# PY32F030xx register map
Vendor: Puya; Series: PY32F0; File version: 1.0.0
CPU: CM0+ r0p1, little endian, no MPU, no FPU, 4 interrupt priority bits
Registers are 32-bit, read-write, reset 0x0 unless marked. A register's access mark holds for its fields unless they carry their own. Offsets are from the block's base; [hi:lo] are bit positions; {n}, {i} and the like mark numbered series; 'fields as' and 'values as' point back to an identical list.

## COMP1 — Comparator
Base 0x40010200
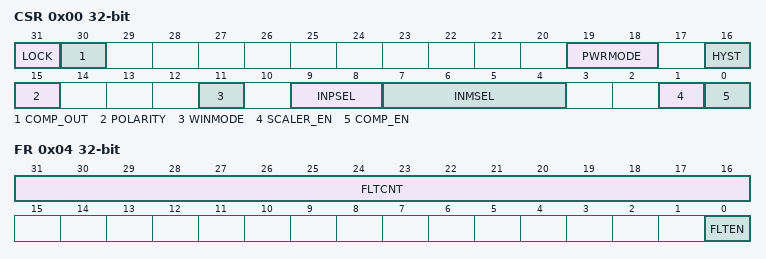
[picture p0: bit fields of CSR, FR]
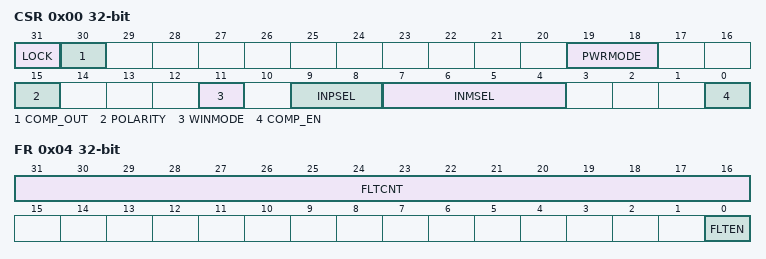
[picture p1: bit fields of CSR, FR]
0x00 CSR — COMP control and status register
  [31] LOCK — CSR register lock
  [30] COMP_OUT — Comparator output status
  [19:18] PWRMODE — Comparator power modeselector
    1=0; 2=1
  [16] HYST — Comparator hysteresis enableselector
  [15] POLARITY — Comparator polarityselector
  [11] WINMODE — Comparator non-inverting inputselector for window mode
  [9:8] INPSEL — Comparator signal selector fornon-inverting input
    1=0; 2=1
  [7:4] INMSEL — Comparator signal selector forinverting input INM
    1=0; 2=1; 4=2; 8=3
  [1] SCALER_EN — SCALER enable bit
  [0] COMP_EN — COMP enable bit
0x04 FR — Comparator Filterregister
  [31:16] FLTCNT — Comparator filter and counter
  [0] FLTEN — Filter enable bit

## COMP2 — Comparator
Base 0x40010210
0x00 CSR — COMP control and status register
  [31] LOCK — CSR register lock
  [30] COMP_OUT — Comparator output status
  [19:18] PWRMODE — Comparator power modeselector
    1=0; 2=1
  [15] POLARITY — Comparator polarityselector
  [11] WINMODE — Comparator non-inverting inputselector for window mode
  [9:8] INPSEL — Comparator signal selector fornon-inverting input
    1=0; 2=1
  [7:4] INMSEL — Comparator signal selector forinverting input INM
    1=0; 2=1; 4=2; 8=3
  [0] COMP_EN — COMP enable bit
0x04 FR — Comparator Filterregister
  [31:16] FLTCNT — Comparator filter and counter
  [0] FLTEN — Filter enable bit

## CRC — CRC calculation unit
Base 0x40023000
0x00 DR reset 0xFFFFFFFF — Data register
  [31:0] DR — Data Register
0x04 IDR — Independent Data register
  [7:0] IDR
0x08 CR wo — Control register
  [0] RESET — Reset bit

## DBGMCU — Debug support
Base 0x40015800
0x00 IDCODE ro — MCU Device ID Code Register
0x04 CR — Debug MCU Configuration Register
  [1] DBG_STOP — Debug Stop Mode
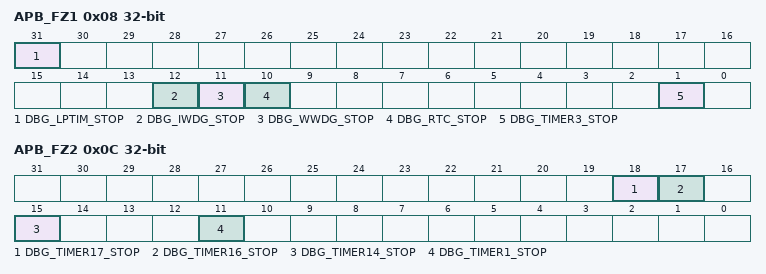
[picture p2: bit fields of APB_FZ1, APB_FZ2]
0x08 APB_FZ1 — APB Freeze Register1
  [31] DBG_LPTIM_STOP — Debug LPTIM stopped when Core is halted
  [12] DBG_IWDG_STOP — Debug Independent Wachdog stopped when Core is halted
  [11] DBG_WWDG_STOP — Debug Window Wachdog stopped when Core is halted
  [10] DBG_RTC_STOP — Debug RTC stopped when Core is halted
  [1] DBG_TIMER3_STOP — Debug Timer 3 stopped when Core is halted
0x0C APB_FZ2 — APB Freeze Register2
  [18] DBG_TIMER17_STOP — Debug Timer 17 stopped when Core is halted
  [17] DBG_TIMER16_STOP — Debug Timer 16 stopped when Core is halted
  [15] DBG_TIMER14_STOP — Debug Timer 14 stopped when Core is halted
  [11] DBG_TIMER1_STOP — Debug Timer 1 stopped when Core is halted

## DMA — Direct memory access
Base 0x40020000
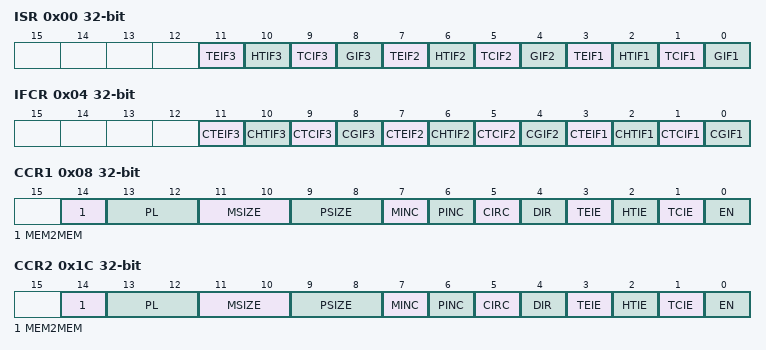
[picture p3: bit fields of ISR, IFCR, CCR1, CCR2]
0x00 ISR ro — DMA interrupt status register(DMA_ISR)
  [11] TEIF3 — Channel 3 Transfer Errorflag
  [10] HTIF3 — Channel 3 Half Transfer Completeflag
  [9] TCIF3 — Channel 3 Transfer Completeflag
  [8] GIF3 — Channel 3 Global interruptflag
  [7] TEIF2 — Channel 2 Transfer Errorflag
  [6] HTIF2 — Channel 2 Half Transfer Completeflag
  [5] TCIF2 — Channel 2 Transfer Completeflag
  [4] GIF2 — Channel 2 Global interruptflag
  [3] TEIF1 — Channel 1 Transfer Errorflag
  [2] HTIF1 — Channel 1 Half Transfer Completeflag
  [1] TCIF1 — Channel 1 Transfer Completeflag
  [0] GIF1 — Channel 1 Global interrupt flag
0x04 IFCR wo — DMA interrupt flag clear register(DMA_IFCR)
  [11] CTEIF3 — Channel 3 Transfer Errorclear
  [10] CHTIF3 — Channel 3 Half Transferclear
  [9] CTCIF3 — Channel 3 Transfer Completeclear
  [8] CGIF3 — Channel 3 Global interruptclear
  [7] CTEIF2 — Channel 2 Transfer Errorclear
  [6] CHTIF2 — Channel 2 Half Transferclear
  [5] CTCIF2 — Channel 2 Transfer Completeclear
  [4] CGIF2 — Channel 2 Global interruptclear
  [3] CTEIF1 — Channel 1 Transfer Errorclear
  [2] CHTIF1 — Channel 1 Half Transferclear
  [1] CTCIF1 — Channel 1 Transfer Completeclear
  [0] CGIF1 — Channel 1 Global interruptclear
0x08 CCR1 — DMA channel configuration register(DMA_CCR)
  [14] MEM2MEM — Memory to memory mode
  [13:12] PL — Channel Priority level
  [11:10] MSIZE — Memory size
  [9:8] PSIZE — Peripheral size
  [7] MINC — Memory increment mode
  [6] PINC — Peripheral increment mode
  [5] CIRC — Circular mode
  [4] DIR — Data transfer direction
  [3] TEIE — Transfer error interruptenable
  [2] HTIE — Half Transfer interruptenable
  [1] TCIE — Transfer complete interruptenable
  [0] EN — Channel enable
0x0C CNDTR1 — DMA channel 1 number of dataregister
  [15:0] NDT — Number of data to transfer
0x10 CPAR1 — DMA channel 1 peripheral addressregister
  [31:0] PA — Peripheral address
{0x0+0x14*i} CMAR{i} (i=1..3) — DMA channel {i} memory addressregister
  [31:0] MA — Memory address
0x1C CCR2 — DMA channel configuration register(DMA_CCR)
  fields as CCR1
0x20 CNDTR2 — DMA channel 2 number of dataregister
  [15:0] NDT — Number of data to transfer
0x24 CPAR2 — DMA channel 2 peripheral addressregister
  [31:0] PA — Peripheral address
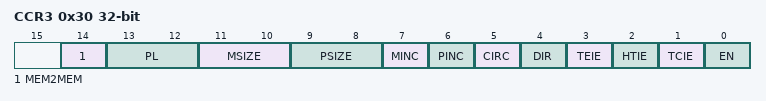
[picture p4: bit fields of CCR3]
0x30 CCR3 — DMA channel configuration register(DMA_CCR)
  fields as CCR1
0x34 CNDTR3 — DMA channel 3 number of dataregister
  [15:0] NDT — Number of data to transfer
0x38 CPAR3 — DMA channel 3 peripheral addressregister
  [31:0] PA — Peripheral address
